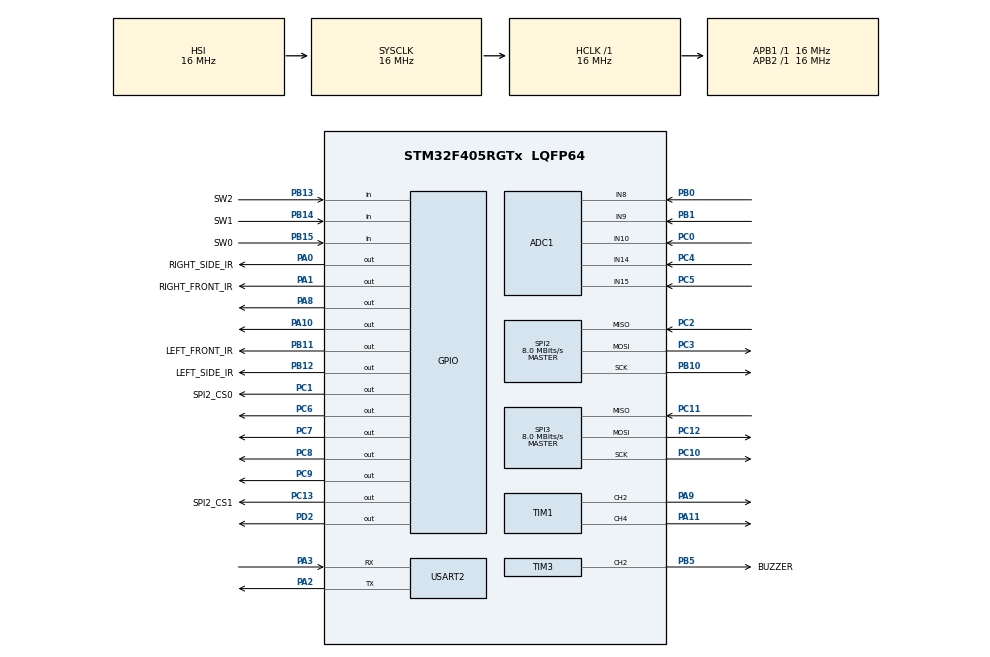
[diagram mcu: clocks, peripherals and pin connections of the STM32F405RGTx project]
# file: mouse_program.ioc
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ADC1.Channel-7\#ChannelRegularConversion=ADC_CHANNEL_8
ADC1.NbrOfConversionFlag=1
ADC1.Rank-7\#ChannelRegularConversion=1
ADC1.SamplingTime-7\#ChannelRegularConversion=ADC_SAMPLETIME_3CYCLES
ADC1.master=1
Mcu.Family=STM32F4
Mcu.Name=STM32F405RGTx
Mcu.Package=LQFP64
NVIC.PriorityGroup=NVIC_PRIORITYGROUP_4
PA0-WKUP.GPIO_Label=RIGHT_SIDE_IR
PA0-WKUP.Signal=GPIO_Output
PA1.GPIO_Label=RIGHT_FRONT_IR
PA1.Signal=GPIO_Output
PA10.Signal=GPIO_Output
PA11.Signal=S_TIM1_CH4
PA13.Mode=Trace_Asynchronous_SW
PA13.Signal=SYS_JTMS-SWDIO
PA14.Mode=Trace_Asynchronous_SW
PA14.Signal=SYS_JTCK-SWCLK
PA2.Mode=Asynchronous
PA2.Signal=USART2_TX
PA3.Mode=Asynchronous
PA3.Signal=USART2_RX
PA8.Signal=GPIO_Output
PA9.Signal=S_TIM1_CH2
PB0.Signal=ADCx_IN8
PB1.Signal=ADCx_IN9
PB10.Mode=Full_Duplex_Master
PB10.Signal=SPI2_SCK
PB11.GPIO_Label=LEFT_FRONT_IR
PB11.Signal=GPIO_Output
PB12.GPIO_Label=LEFT_SIDE_IR
PB12.Signal=GPIO_Output
PB13.GPIO_Label=SW2
PB13.Signal=GPIO_Input
PB14.GPIO_Label=SW1
PB14.Signal=GPIO_Input
PB15.GPIO_Label=SW0
PB15.Signal=GPIO_Input
PB3.Mode=Trace_Asynchronous_SW
PB3.Signal=SYS_JTDO-SWO
PB5.GPIO_Label=BUZZER
PB5.Signal=S_TIM3_CH2
PC0.Signal=ADCx_IN10
PC1.GPIO_Label=SPI2_CS0
PC1.Signal=GPIO_Output
PC10.Mode=Full_Duplex_Master
PC10.Signal=SPI3_SCK
PC11.Mode=Full_Duplex_Master
PC11.Signal=SPI3_MISO
PC12.Mode=Full_Duplex_Master
PC12.Signal=SPI3_MOSI
PC13-ANTI_TAMP.GPIO_Label=SPI2_CS1
PC13-ANTI_TAMP.Signal=GPIO_Output
PC2.Mode=Full_Duplex_Master
PC2.Signal=SPI2_MISO
PC3.Mode=Full_Duplex_Master
PC3.Signal=SPI2_MOSI
PC4.Signal=ADCx_IN14
PC5.Signal=ADCx_IN15
PC6.Signal=GPIO_Output
PC7.Signal=GPIO_Output
PC8.Signal=GPIO_Output
PC9.Signal=GPIO_Output
PD2.Signal=GPIO_Output
ProjectManager.HeapSize=0x200
ProjectManager.StackSize=0x400
ProjectManager.TargetToolchain=Makefile
RCC.AHBFreq_Value=16000000
RCC.APB1Freq_Value=16000000
RCC.APB2Freq_Value=16000000
RCC.CortexFreq_Value=16000000
RCC.HSE_VALUE=25000000
RCC.HSI_VALUE=16000000
RCC.LSE_VALUE=32768
RCC.SYSCLKFreq_VALUE=16000000
RCC.VCOOutputFreq_Value=192000000
SH.ADCx_IN10.0=ADC3_IN10
SH.ADCx_IN10.1=ADC1_IN10,IN10
SH.ADCx_IN14.0=ADC1_IN14,IN14
SH.ADCx_IN15.0=ADC1_IN15,IN15
SH.ADCx_IN8.0=ADC1_IN8,IN8
SH.ADCx_IN9.0=ADC1_IN9,IN9
SH.S_TIM1_CH2.0=TIM1_CH2,PWM Generation2 CH2
SH.S_TIM1_CH4.0=TIM1_CH4,PWM Generation4 CH4
SH.S_TIM3_CH2.0=TIM3_CH2,PWM Generation2 CH2
SPI2.CalculateBaudRate=8.0 MBits/s
SPI2.Direction=SPI_DIRECTION_2LINES
SPI2.Mode=SPI_MODE_MASTER
SPI2.VirtualType=VM_MASTER
SPI3.CalculateBaudRate=8.0 MBits/s
SPI3.Direction=SPI_DIRECTION_2LINES
SPI3.Mode=SPI_MODE_MASTER
SPI3.VirtualType=VM_MASTER
TIM1.Channel-PWM\ Generation2\ CH2=TIM_CHANNEL_2
TIM1.Channel-PWM\ Generation4\ CH4=TIM_CHANNEL_4
TIM3.Channel-PWM\ Generation2\ CH2=TIM_CHANNEL_2
USART2.VirtualMode=VM_ASYNC
VP_TIM1_VS_ClockSourceINT.Mode=Internal
VP_TIM2_VS_ClockSourceINT.Mode=Internal
VP_TIM3_VS_ClockSourceINT.Mode=Internal
board=custom

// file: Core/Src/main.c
/* USER CODE BEGIN Header */
/**
  ******************************************************************************
  * @file           : main.c
  * @brief          : Main program body
  ******************************************************************************
  * @attention
  *
  * Copyright (c) 2022 STMicroelectronics.
  * All rights reserved.
  *
  * This software is licensed under terms that can be found in the LICENSE file
  * in the root directory of this software component.
  * If no LICENSE file comes with this software, it is provided AS-IS.
  *
  ******************************************************************************
  */
/* USER CODE END Header */
#include "main.h"

ADC_HandleTypeDef hadc1;

SPI_HandleTypeDef hspi2;
SPI_HandleTypeDef hspi3;

TIM_HandleTypeDef htim1;
TIM_HandleTypeDef htim2;
TIM_HandleTypeDef htim3;

UART_HandleTypeDef huart2;

void SystemClock_Config(void);
static void MX_GPIO_Init(void);
static void MX_ADC1_Init(void);
static void MX_SPI2_Init(void);
static void MX_TIM1_Init(void);
static void MX_TIM2_Init(void);
static void MX_TIM3_Init(void);
static void MX_USART2_UART_Init(void);
static void MX_SPI3_Init(void);

int main(void)
{

  /* MCU Configuration--------------------------------------------------------*/

  /* Reset of all peripherals, Initializes the Flash interface and the Systick. */
  HAL_Init();

  /* Configure the system clock */
  SystemClock_Config();

  /* Initialize all configured peripherals */
  MX_GPIO_Init();
  MX_ADC1_Init();
  MX_SPI2_Init();
  MX_TIM1_Init();
  MX_TIM2_Init();
  MX_TIM3_Init();
  MX_USART2_UART_Init();
  MX_SPI3_Init();

  /* Infinite loop */
  /* USER CODE BEGIN WHILE */
  while (1)
  {
    HAL_GPIO_TogglePin(GPIOC, GPIO_PIN_9);
    HAL_GPIO_TogglePin(GPIOC, GPIO_PIN_8);
    HAL_Delay(500);
    /* USER CODE END WHILE */

  }
}

void SystemClock_Config(void)
{
  RCC_OscInitTypeDef RCC_OscInitStruct = {0};
  RCC_ClkInitTypeDef RCC_ClkInitStruct = {0};

  /** Configure the main internal regulator output voltage
  */
  __HAL_RCC_PWR_CLK_ENABLE();
  __HAL_PWR_VOLTAGESCALING_CONFIG(PWR_REGULATOR_VOLTAGE_SCALE1);

  /** Initializes the RCC Oscillators according to the specified parameters
  * in the RCC_OscInitTypeDef structure.
  */
  RCC_OscInitStruct.OscillatorType = RCC_OSCILLATORTYPE_HSI;
  RCC_OscInitStruct.HSIState = RCC_HSI_ON;
  RCC_OscInitStruct.HSICalibrationValue = RCC_HSICALIBRATION_DEFAULT;
  RCC_OscInitStruct.PLL.PLLState = RCC_PLL_NONE;
  if (HAL_RCC_OscConfig(&RCC_OscInitStruct) != HAL_OK)
  {
    Error_Handler();
  }

  /** Initializes the CPU, AHB and APB buses clocks
  */
  RCC_ClkInitStruct.ClockType = RCC_CLOCKTYPE_HCLK|RCC_CLOCKTYPE_SYSCLK
                              |RCC_CLOCKTYPE_PCLK1|RCC_CLOCKTYPE_PCLK2;
  RCC_ClkInitStruct.SYSCLKSource = RCC_SYSCLKSOURCE_HSI;
  RCC_ClkInitStruct.AHBCLKDivider = RCC_SYSCLK_DIV1;
  RCC_ClkInitStruct.APB1CLKDivider = RCC_HCLK_DIV1;
  RCC_ClkInitStruct.APB2CLKDivider = RCC_HCLK_DIV1;

  if (HAL_RCC_ClockConfig(&RCC_ClkInitStruct, FLASH_LATENCY_0) != HAL_OK)
  {
    Error_Handler();
  }
}

static void MX_ADC1_Init(void)
{

  ADC_ChannelConfTypeDef sConfig = {0};

  /** Configure the global features of the ADC (Clock, Resolution, Data Alignment and number of conversion)
  */
  hadc1.Instance = ADC1;
  hadc1.Init.ClockPrescaler = ADC_CLOCK_SYNC_PCLK_DIV2;
  hadc1.Init.Resolution = ADC_RESOLUTION_12B;
  hadc1.Init.ScanConvMode = DISABLE;
  hadc1.Init.ContinuousConvMode = DISABLE;
  hadc1.Init.DiscontinuousConvMode = DISABLE;
  hadc1.Init.ExternalTrigConvEdge = ADC_EXTERNALTRIGCONVEDGE_NONE;
  hadc1.Init.ExternalTrigConv = ADC_SOFTWARE_START;
  hadc1.Init.DataAlign = ADC_DATAALIGN_RIGHT;
  hadc1.Init.NbrOfConversion = 1;
  hadc1.Init.DMAContinuousRequests = DISABLE;
  hadc1.Init.EOCSelection = ADC_EOC_SINGLE_CONV;
  if (HAL_ADC_Init(&hadc1) != HAL_OK)
  {
    Error_Handler();
  }

  /** Configure for the selected ADC regular channel its corresponding rank in the sequencer and its sample time.
  */
  sConfig.Channel = ADC_CHANNEL_8;
  sConfig.Rank = 1;
  sConfig.SamplingTime = ADC_SAMPLETIME_3CYCLES;
  if (HAL_ADC_ConfigChannel(&hadc1, &sConfig) != HAL_OK)
  {
    Error_Handler();
  }

}

static void MX_SPI2_Init(void)
{

  /* SPI2 parameter configuration*/
  hspi2.Instance = SPI2;
  hspi2.Init.Mode = SPI_MODE_MASTER;
  hspi2.Init.Direction = SPI_DIRECTION_2LINES;
  hspi2.Init.DataSize = SPI_DATASIZE_8BIT;
  hspi2.Init.CLKPolarity = SPI_POLARITY_LOW;
  hspi2.Init.CLKPhase = SPI_PHASE_1EDGE;
  hspi2.Init.NSS = SPI_NSS_SOFT;
  hspi2.Init.BaudRatePrescaler = SPI_BAUDRATEPRESCALER_2;
  hspi2.Init.FirstBit = SPI_FIRSTBIT_MSB;
  hspi2.Init.TIMode = SPI_TIMODE_DISABLE;
  hspi2.Init.CRCCalculation = SPI_CRCCALCULATION_DISABLE;
  hspi2.Init.CRCPolynomial = 10;
  if (HAL_SPI_Init(&hspi2) != HAL_OK)
  {
    Error_Handler();
  }

}

static void MX_SPI3_Init(void)
{

  /* SPI3 parameter configuration*/
  hspi3.Instance = SPI3;
  hspi3.Init.Mode = SPI_MODE_MASTER;
  hspi3.Init.Direction = SPI_DIRECTION_2LINES;
  hspi3.Init.DataSize = SPI_DATASIZE_8BIT;
  hspi3.Init.CLKPolarity = SPI_POLARITY_LOW;
  hspi3.Init.CLKPhase = SPI_PHASE_1EDGE;
  hspi3.Init.NSS = SPI_NSS_SOFT;
  hspi3.Init.BaudRatePrescaler = SPI_BAUDRATEPRESCALER_2;
  hspi3.Init.FirstBit = SPI_FIRSTBIT_MSB;
  hspi3.Init.TIMode = SPI_TIMODE_DISABLE;
  hspi3.Init.CRCCalculation = SPI_CRCCALCULATION_DISABLE;
  hspi3.Init.CRCPolynomial = 10;
  if (HAL_SPI_Init(&hspi3) != HAL_OK)
  {
    Error_Handler();
  }

}

static void MX_TIM1_Init(void)
{

  TIM_ClockConfigTypeDef sClockSourceConfig = {0};
  TIM_MasterConfigTypeDef sMasterConfig = {0};
  TIM_OC_InitTypeDef sConfigOC = {0};
  TIM_BreakDeadTimeConfigTypeDef sBreakDeadTimeConfig = {0};

  htim1.Instance = TIM1;
  htim1.Init.Prescaler = 0;
  htim1.Init.CounterMode = TIM_COUNTERMODE_UP;
  htim1.Init.Period = 65535;
  htim1.Init.ClockDivision = TIM_CLOCKDIVISION_DIV1;
  htim1.Init.RepetitionCounter = 0;
  htim1.Init.AutoReloadPreload = TIM_AUTORELOAD_PRELOAD_DISABLE;
  if (HAL_TIM_Base_Init(&htim1) != HAL_OK)
  {
    Error_Handler();
  }
  sClockSourceConfig.ClockSource = TIM_CLOCKSOURCE_INTERNAL;
  if (HAL_TIM_ConfigClockSource(&htim1, &sClockSourceConfig) != HAL_OK)
  {
    Error_Handler();
  }
  if (HAL_TIM_PWM_Init(&htim1) != HAL_OK)
  {
    Error_Handler();
  }
  sMasterConfig.MasterOutputTrigger = TIM_TRGO_RESET;
  sMasterConfig.MasterSlaveMode = TIM_MASTERSLAVEMODE_DISABLE;
  if (HAL_TIMEx_MasterConfigSynchronization(&htim1, &sMasterConfig) != HAL_OK)
  {
    Error_Handler();
  }
  sConfigOC.OCMode = TIM_OCMODE_PWM1;
  sConfigOC.Pulse = 0;
  sConfigOC.OCPolarity = TIM_OCPOLARITY_HIGH;
  sConfigOC.OCNPolarity = TIM_OCNPOLARITY_HIGH;
  sConfigOC.OCFastMode = TIM_OCFAST_DISABLE;
  sConfigOC.OCIdleState = TIM_OCIDLESTATE_RESET;
  sConfigOC.OCNIdleState = TIM_OCNIDLESTATE_RESET;
  if (HAL_TIM_PWM_ConfigChannel(&htim1, &sConfigOC, TIM_CHANNEL_2) != HAL_OK)
  {
    Error_Handler();
  }
  if (HAL_TIM_PWM_ConfigChannel(&htim1, &sConfigOC, TIM_CHANNEL_4) != HAL_OK)
  {
    Error_Handler();
  }
  sBreakDeadTimeConfig.OffStateRunMode = TIM_OSSR_DISABLE;
  sBreakDeadTimeConfig.OffStateIDLEMode = TIM_OSSI_DISABLE;
  sBreakDeadTimeConfig.LockLevel = TIM_LOCKLEVEL_OFF;
  sBreakDeadTimeConfig.DeadTime = 0;
  sBreakDeadTimeConfig.BreakState = TIM_BREAK_DISABLE;
  sBreakDeadTimeConfig.BreakPolarity = TIM_BREAKPOLARITY_HIGH;
  sBreakDeadTimeConfig.AutomaticOutput = TIM_AUTOMATICOUTPUT_DISABLE;
  if (HAL_TIMEx_ConfigBreakDeadTime(&htim1, &sBreakDeadTimeConfig) != HAL_OK)
  {
    Error_Handler();
  }
  HAL_TIM_MspPostInit(&htim1);

}

static void MX_TIM2_Init(void)
{

  TIM_ClockConfigTypeDef sClockSourceConfig = {0};
  TIM_MasterConfigTypeDef sMasterConfig = {0};

  htim2.Instance = TIM2;
  htim2.Init.Prescaler = 0;
  htim2.Init.CounterMode = TIM_COUNTERMODE_UP;
  htim2.Init.Period = 4294967295;
  htim2.Init.ClockDivision = TIM_CLOCKDIVISION_DIV1;
  htim2.Init.AutoReloadPreload = TIM_AUTORELOAD_PRELOAD_DISABLE;
  if (HAL_TIM_Base_Init(&htim2) != HAL_OK)
  {
    Error_Handler();
  }
  sClockSourceConfig.ClockSource = TIM_CLOCKSOURCE_INTERNAL;
  if (HAL_TIM_ConfigClockSource(&htim2, &sClockSourceConfig) != HAL_OK)
  {
    Error_Handler();
  }
  sMasterConfig.MasterOutputTrigger = TIM_TRGO_RESET;
  sMasterConfig.MasterSlaveMode = TIM_MASTERSLAVEMODE_DISABLE;
  if (HAL_TIMEx_MasterConfigSynchronization(&htim2, &sMasterConfig) != HAL_OK)
  {
    Error_Handler();
  }

}

static void MX_TIM3_Init(void)
{

  TIM_ClockConfigTypeDef sClockSourceConfig = {0};
  TIM_MasterConfigTypeDef sMasterConfig = {0};
  TIM_OC_InitTypeDef sConfigOC = {0};

  htim3.Instance = TIM3;
  htim3.Init.Prescaler = 0;
  htim3.Init.CounterMode = TIM_COUNTERMODE_UP;
  htim3.Init.Period = 65535;
  htim3.Init.ClockDivision = TIM_CLOCKDIVISION_DIV1;
  htim3.Init.AutoReloadPreload = TIM_AUTORELOAD_PRELOAD_DISABLE;
  if (HAL_TIM_Base_Init(&htim3) != HAL_OK)
  {
    Error_Handler();
  }
  sClockSourceConfig.ClockSource = TIM_CLOCKSOURCE_INTERNAL;
  if (HAL_TIM_ConfigClockSource(&htim3, &sClockSourceConfig) != HAL_OK)
  {
    Error_Handler();
  }
  if (HAL_TIM_PWM_Init(&htim3) != HAL_OK)
  {
    Error_Handler();
  }
  sMasterConfig.MasterOutputTrigger = TIM_TRGO_RESET;
  sMasterConfig.MasterSlaveMode = TIM_MASTERSLAVEMODE_DISABLE;
  if (HAL_TIMEx_MasterConfigSynchronization(&htim3, &sMasterConfig) != HAL_OK)
  {
    Error_Handler();
  }
  sConfigOC.OCMode = TIM_OCMODE_PWM1;
  sConfigOC.Pulse = 0;
  sConfigOC.OCPolarity = TIM_OCPOLARITY_HIGH;
  sConfigOC.OCFastMode = TIM_OCFAST_DISABLE;
  if (HAL_TIM_PWM_ConfigChannel(&htim3, &sConfigOC, TIM_CHANNEL_2) != HAL_OK)
  {
    Error_Handler();
  }
  HAL_TIM_MspPostInit(&htim3);

}

static void MX_USART2_UART_Init(void)
{

  huart2.Instance = USART2;
  huart2.Init.BaudRate = 115200;
  huart2.Init.WordLength = UART_WORDLENGTH_8B;
  huart2.Init.StopBits = UART_STOPBITS_1;
  huart2.Init.Parity = UART_PARITY_NONE;
  huart2.Init.Mode = UART_MODE_TX_RX;
  huart2.Init.HwFlowCtl = UART_HWCONTROL_NONE;
  huart2.Init.OverSampling = UART_OVERSAMPLING_16;
  if (HAL_UART_Init(&huart2) != HAL_OK)
  {
    Error_Handler();
  }

}

static void MX_GPIO_Init(void)
{
  GPIO_InitTypeDef GPIO_InitStruct = {0};

  /* GPIO Ports Clock Enable */
  __HAL_RCC_GPIOC_CLK_ENABLE();
  __HAL_RCC_GPIOA_CLK_ENABLE();
  __HAL_RCC_GPIOB_CLK_ENABLE();
  __HAL_RCC_GPIOD_CLK_ENABLE();

  /*Configure GPIO pin Output Level */
  HAL_GPIO_WritePin(GPIOC, SPI2_CS1_Pin|SPI2_CS0_Pin|GPIO_PIN_6|GPIO_PIN_7
                          |GPIO_PIN_8|GPIO_PIN_9, GPIO_PIN_RESET);

  /*Configure GPIO pin Output Level */
  HAL_GPIO_WritePin(GPIOA, RIGHT_SIDE_IR_Pin|RIGHT_FRONT_IR_Pin|GPIO_PIN_8|GPIO_PIN_10, GPIO_PIN_RESET);

  /*Configure GPIO pin Output Level */
  HAL_GPIO_WritePin(GPIOB, LEFT_FRONT_IR_Pin|LEFT_SIDE_IR_Pin, GPIO_PIN_RESET);

  /*Configure GPIO pin Output Level */
  HAL_GPIO_WritePin(GPIOD, GPIO_PIN_2, GPIO_PIN_RESET);

  /*Configure GPIO pins : SPI2_CS1_Pin SPI2_CS0_Pin PC6 PC7
                           PC8 PC9 */
  GPIO_InitStruct.Pin = SPI2_CS1_Pin|SPI2_CS0_Pin|GPIO_PIN_6|GPIO_PIN_7
                          |GPIO_PIN_8|GPIO_PIN_9;
  GPIO_InitStruct.Mode = GPIO_MODE_OUTPUT_PP;
  GPIO_InitStruct.Pull = GPIO_NOPULL;
  GPIO_InitStruct.Speed = GPIO_SPEED_FREQ_LOW;
  HAL_GPIO_Init(GPIOC, &GPIO_InitStruct);

  /*Configure GPIO pin : PC0 */
  GPIO_InitStruct.Pin = GPIO_PIN_0;
  GPIO_InitStruct.Mode = GPIO_MODE_ANALOG;
  GPIO_InitStruct.Pull = GPIO_NOPULL;
  HAL_GPIO_Init(GPIOC, &GPIO_InitStruct);

  /*Configure GPIO pins : RIGHT_SIDE_IR_Pin RIGHT_FRONT_IR_Pin PA8 PA10 */
  GPIO_InitStruct.Pin = RIGHT_SIDE_IR_Pin|RIGHT_FRONT_IR_Pin|GPIO_PIN_8|GPIO_PIN_10;
  GPIO_InitStruct.Mode = GPIO_MODE_OUTPUT_PP;
  GPIO_InitStruct.Pull = GPIO_NOPULL;
  GPIO_InitStruct.Speed = GPIO_SPEED_FREQ_LOW;
  HAL_GPIO_Init(GPIOA, &GPIO_InitStruct);

  /*Configure GPIO pins : LEFT_FRONT_IR_Pin LEFT_SIDE_IR_Pin */
  GPIO_InitStruct.Pin = LEFT_FRONT_IR_Pin|LEFT_SIDE_IR_Pin;
  GPIO_InitStruct.Mode = GPIO_MODE_OUTPUT_PP;
  GPIO_InitStruct.Pull = GPIO_NOPULL;
  GPIO_InitStruct.Speed = GPIO_SPEED_FREQ_LOW;
  HAL_GPIO_Init(GPIOB, &GPIO_InitStruct);

  /*Configure GPIO pins : SW2_Pin SW1_Pin SW0_Pin */
  GPIO_InitStruct.Pin = SW2_Pin|SW1_Pin|SW0_Pin;
  GPIO_InitStruct.Mode = GPIO_MODE_INPUT;
  GPIO_InitStruct.Pull = GPIO_NOPULL;
  HAL_GPIO_Init(GPIOB, &GPIO_InitStruct);

  /*Configure GPIO pin : PD2 */
  GPIO_InitStruct.Pin = GPIO_PIN_2;
  GPIO_InitStruct.Mode = GPIO_MODE_OUTPUT_PP;
  GPIO_InitStruct.Pull = GPIO_NOPULL;
  GPIO_InitStruct.Speed = GPIO_SPEED_FREQ_LOW;
  HAL_GPIO_Init(GPIOD, &GPIO_InitStruct);

}

void Error_Handler(void)
{
  __disable_irq();
  while (1)
  {
  }
}
